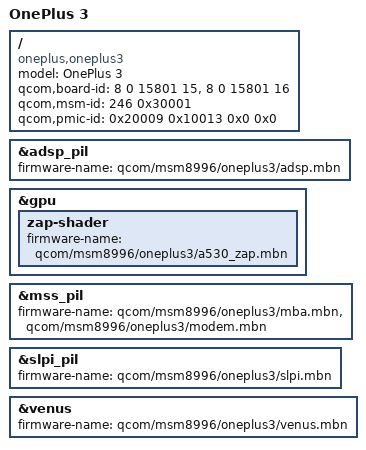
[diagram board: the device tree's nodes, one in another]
// SPDX-License-Identifier: GPL-2.0-only

/dts-v1/;

#include "msm8996.dtsi"
#include "msm8996-oneplus3.dtsi"

/ {
	model = "OnePlus 3";
	compatible = "oneplus,oneplus3", "qcom,msm8996";
	qcom,board-id = <8 0 15801 15>, <8 0 15801 16>;
	qcom,msm-id = <246 0x30001>;
	qcom,pmic-id = <0x20009 0x10013 0x0 0x0>;
};

&adsp_pil {
	firmware-name = "qcom/msm8996/oneplus3/adsp.mbn";
};

&gpu {
	zap-shader {
		firmware-name = "qcom/msm8996/oneplus3/a530_zap.mbn";
	};
};

&mss_pil {
	firmware-name = "qcom/msm8996/oneplus3/mba.mbn",
			"qcom/msm8996/oneplus3/modem.mbn";
};

&slpi_pil {
	firmware-name = "qcom/msm8996/oneplus3/slpi.mbn";
};

&venus {
	firmware-name = "qcom/msm8996/oneplus3/venus.mbn";
};
